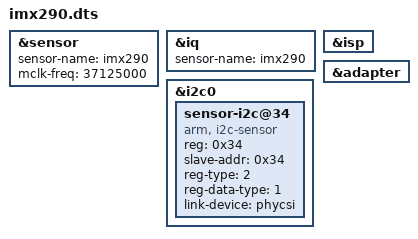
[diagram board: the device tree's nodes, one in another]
/dts-v1/;
/plugin/;

//
// JeVois-pro overlay to enable IMX290 camera sensor
//

/ {
    // JEVOIS: camera sensor:
	fragment@0 {
		target = <&sensor>;

		__overlay__ {
			status = "okay";
            sensor-name = "imx290"; // Currently supported are: imx290, os08a10, imx227

            mclk-freq = <37125000>; // JEVOIS custom param: set mclock frequency
		};
	};

    // JEVOIS: camera sensor image quality (IQ) module:
	fragment@1 {
		target = <&iq>;

		__overlay__ {
			status = "okay";
            sensor-name = "imx290"; // Currently supported are: imx290, os08a10, imx227
		};
	};

    // JEVOIS: camera sensor image signal processor (ISP) hardware support:
	fragment@2 {
		target = <&isp>;

		__overlay__ {
			status = "okay";
		};
	};

    // JEVOIS: camera sensor adapter
	fragment@3 {
		target = <&adapter>;

		__overlay__ {
			status = "okay";
		};
	};

    // JEVOIS: Camera sensor I2C uses i2c0 on the M.2 camera connector:
	fragment@4 {
        //target = <&i2c2>; // FIXME: PROTO only
        target = <&i2c0>; // FIXME: Production units

		__overlay__ {
	        status = "okay";

			#address-cells = <1>;
			#size-cells = <0>;

            // JEVOIS: IMX290 SCCB address is 0x34/0x35
            sensor-i2c@34 {
                status = "okay";
    	        compatible = "arm, i2c-sensor";
    	        reg = <0x34>;
    	        reg-names = "i2c-sensor";
    	        slave-addr = <0x34>;
    	        reg-type = <2>;
    	        reg-data-type = <1>;
    	        link-device = <&phycsi>;
            };
        };
	};
};
